VERSION ""

NS_ :

BS_:

BU_: XXX RADAR

BO_ 85 EPB: 8 XXX
 SG_ EPB_ActiveFlag : 40|1@1+ (1,0) [0|1] "" XXX
 SG_ CheckSum : 56|8@1+ (1,0) [0|255] "" XXX

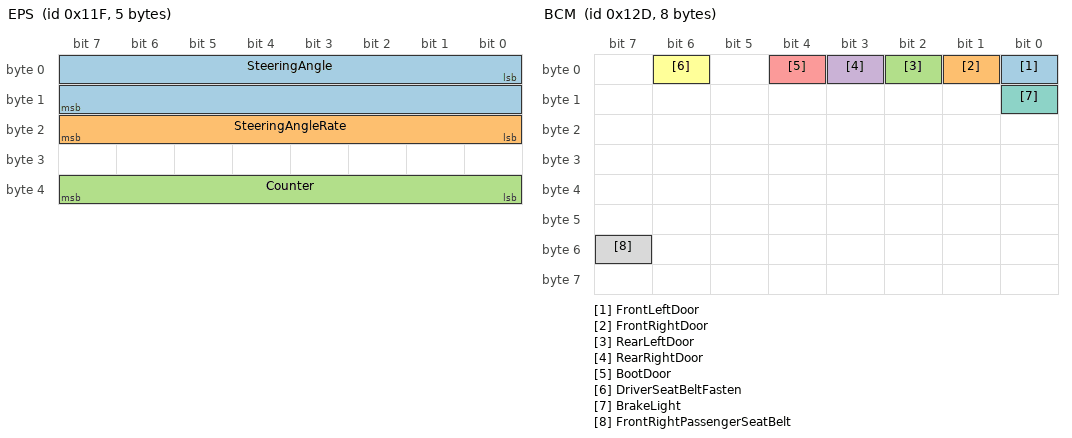
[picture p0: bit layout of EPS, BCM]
BO_ 287 EPS: 5 XXX
 SG_ SteeringAngle : 0|16@1- (0.1,0) [-450|450] "" XXX
 SG_ SteeringAngleRate : 16|8@1+ (4,0) [0|1020] "" XXX
 SG_ Counter : 32|8@1+ (1,0) [0|255] "" XXX

BO_ 289 CARSPEED: 8 XXX
 SG_ CarDisplaySpeed : 0|12@1+ (1,0) [0|255] "" XXX

BO_ 301 BCM: 8 XXX
 SG_ FrontLeftDoor : 0|1@0+ (1,0) [0|1] "" XXX
 SG_ FrontRightDoor : 1|1@0+ (1,0) [0|1] "" XXX
 SG_ RearLeftDoor : 2|1@0+ (1,0) [0|1] "" XXX
 SG_ RearRightDoor : 3|1@0+ (1,0) [0|1] "" XXX
 SG_ BootDoor : 4|1@0+ (1,0) [0|1] "" XXX
 SG_ DriverSeatBeltFasten : 6|1@0+ (1,0) [0|1] "" XXX
 SG_ BrakeLight : 8|1@0+ (1,0) [0|1] "" XXX
 SG_ FrontRightPassengerSeatBelt : 55|1@0+ (1,0) [0|1] "" XXX

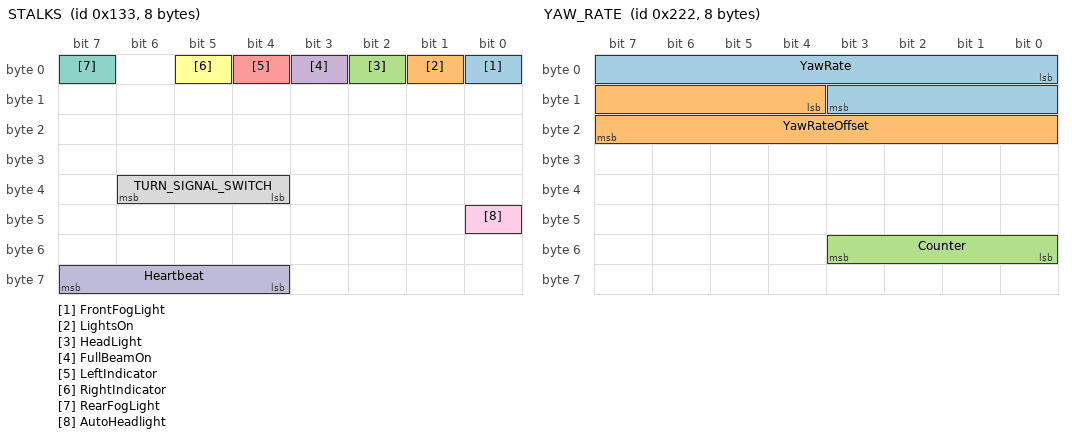
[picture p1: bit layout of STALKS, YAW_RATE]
BO_ 307 STALKS: 8 XXX
 SG_ FrontFogLight : 0|1@0+ (1,0) [0|1] "" XXX
 SG_ LightsOn : 1|1@1+ (1,0) [0|1] "" XXX
 SG_ HeadLight : 2|1@1+ (1,0) [0|1] "" XXX
 SG_ FullBeamOn : 3|1@1+ (1,0) [0|1] "" XXX
 SG_ LeftIndicator : 4|1@0+ (1,0) [0|1] "" XXX
 SG_ RightIndicator : 5|1@0+ (1,0) [0|1] "" XXX
 SG_ RearFogLight : 7|1@0+ (1,0) [0|1] "" XXX
 SG_ TURN_SIGNAL_SWITCH : 36|3@1+ (1,0) [0|7] "" XXX
 SG_ AutoHeadlight : 40|1@0+ (1,0) [0|1] "" XXX
 SG_ Heartbeat : 63|4@0+ (1,0) [0|15] "" XXX

BO_ 546 YAW_RATE: 8 XXX
 SG_ YawRate : 0|12@1+ (0.002133,-2.094) [-2|2] "rad/s" XXX
 SG_ YawRateOffset : 12|12@1+ (0.002133,-0.13) [-0.1|0.1] "rad/s" XXX
 SG_ Counter : 48|4@1+ (1,0) [0|15] "" XXX

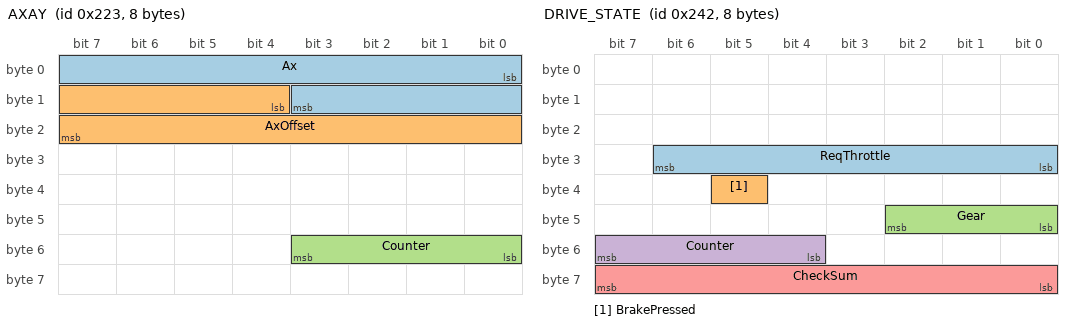
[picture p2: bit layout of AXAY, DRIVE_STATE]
BO_ 547 AXAY: 8 XXX
 SG_ Ax : 0|12@1+ (0.027167,-21.593) [-10|10] "m/s^2" XXX
 SG_ AxOffset : 12|12@1+ (0.027127,-21.593) [-1|1] "m/s^2" XXX
 SG_ Counter : 48|4@1+ (1,0) [0|15] "" XXX

BO_ 578 DRIVE_STATE: 8 XXX
 SG_ ReqThrottle : 30|7@0+ (1,0) [0|127] "" XXX
 SG_ BrakePressed : 37|1@0+ (1,0) [0|1] "" XXX
 SG_ Gear : 40|3@1+ (1,0) [0|7] "" XXX
 SG_ Counter : 55|4@0+ (1,0) [0|15] "" XXX
 SG_ CheckSum : 56|8@1+ (1,0) [0|255] "" XXX

BO_ 660 BELT: 8 XXX
 SG_ SeatBeat : 16|2@1+ (1,0) [0|3] "" XXX

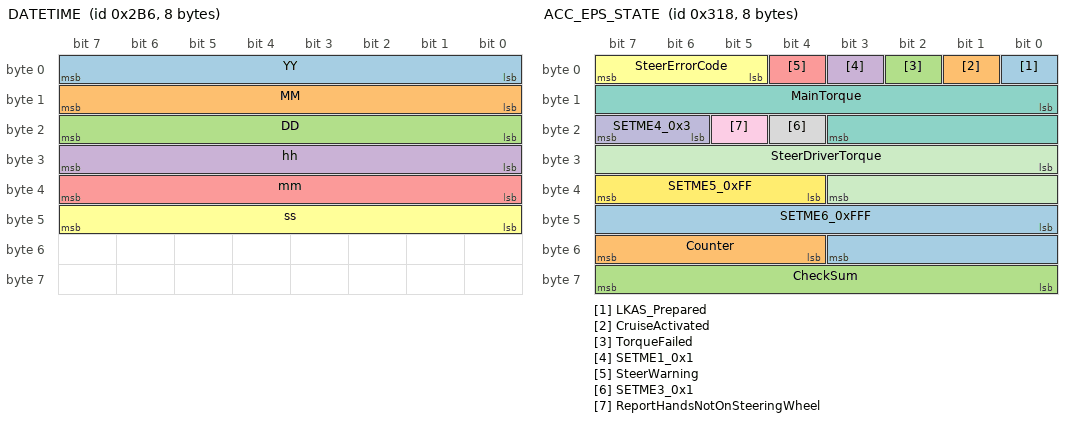
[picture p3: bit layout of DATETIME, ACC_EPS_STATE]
BO_ 694 DATETIME: 8 XXX
 SG_ YY : 7|8@0+ (1,0) [0|255] "" XXX
 SG_ MM : 15|8@0+ (1,0) [0|255] "" XXX
 SG_ DD : 23|8@0+ (1,0) [0|255] "" XXX
 SG_ hh : 31|8@0+ (1,0) [0|255] "" XXX
 SG_ mm : 39|8@0+ (1,0) [0|255] "" XXX
 SG_ ss : 47|8@0+ (1,0) [0|255] "" XXX

BO_ 790 ACC_MPC_STATE: 8 XXX
 SG_ AutoFullBeamState : 3|4@0+ (1,0) [0|1] "" XXX
 SG_ LeftLaneState : 4|2@1+ (1,0) [0|3] "" XXX
 SG_ LKAS_Config : 6|2@1+ (1,0) [0|3] "" XXX
 SG_ SETME2_0x1 : 8|2@1+ (1,0) [0|3] "" XXX
 SG_ ReqHandsOnSteeringWheel : 10|1@1+ (1,0) [0|1] "" XXX
 SG_ MPC_State : 11|4@1+ (1,0) [0|1] "" XXX
 SG_ AutoFullBeam_OnOff : 15|1@0+ (1,0) [0|1] "" XXX
 SG_ LKAS_Output : 16|11@1- (1,0) [-1024|1023] "" XXX
 SG_ LKAS_ReqPrepare : 27|1@1+ (1,0) [0|1] "" XXX
 SG_ LKAS_Active : 28|1@1+ (1,0) [0|3] "" XXX
 SG_ SETME3_0x0 : 29|1@0+ (1,0) [0|1] "" XXX
 SG_ TrafficSignRecognition_OnOff : 30|1@0+ (1,0) [0|1] "" XXX
 SG_ SETME4_0x0 : 31|1@0+ (1,0) [0|1] "" XXX
 SG_ SETME5_0x1 : 32|2@1+ (1,0) [0|3] "" XXX
 SG_ RightLaneState : 34|2@1+ (1,0) [0|3] "" XXX
 SG_ LKAS_State : 36|4@1+ (1,0) [0|3] "" XXX
 SG_ TrafficSignRecognition_Result : 40|8@1+ (5,-5) [-5|1270] "" XXX
 SG_ LKAS_AlarmType : 49|2@0+ (1,0) [0|3] "" XXX
 SG_ SETME7_0x3 : 51|2@0+ (1,0) [0|3] "" XXX
 SG_ Counter : 52|4@1+ (1,0) [0|15] "" XXX
 SG_ CheckSum : 56|8@1+ (1,0) [0|15] "" XXX

BO_ 792 ACC_EPS_STATE: 8 XXX
 SG_ LKAS_Prepared : 0|1@1+ (1,0) [0|1] "" XXX
 SG_ CruiseActivated : 1|1@1+ (1,0) [0|1] "" XXX
 SG_ TorqueFailed : 2|1@1+ (1,0) [0|1] "" XXX
 SG_ SETME1_0x1 : 3|1@1+ (1,0) [0|1] "" XXX
 SG_ SteerWarning : 4|1@1+ (1,0) [0|1] "" XXX
 SG_ SteerErrorCode : 5|3@1+ (1,0) [0|1] "" XXX
 SG_ MainTorque : 8|12@1- (1,0) [-2048|2047] "" XXX
 SG_ SETME3_0x1 : 20|1@1+ (1,0) [0|1] "" XXX
 SG_ ReportHandsNotOnSteeringWheel : 21|1@1+ (1,0) [0|1] "" XXX
 SG_ SETME4_0x3 : 22|2@1+ (1,0) [0|15] "" XXX
 SG_ SteerDriverTorque : 24|12@1- (1,0) [-2048|2047] "" XXX
 SG_ SETME5_0xFF : 36|4@1+ (1,0) [0|15] "" XXX
 SG_ SETME6_0xFFF : 40|12@1+ (1,0) [0|4095] "" XXX
 SG_ Counter : 52|4@1+ (1,0) [0|15] "" XXX
 SG_ CheckSum : 56|8@1+ (1,0) [0|255] "" XXX

BO_ 813 ACC_HUD_ADAS: 8 XXX
 SG_ SetSpeed : 0|9@1+ (0.5,0) [0|255.5] "" XXX
 SG_ HasLead : 9|1@1+ (1,0) [0|1] "" XXX
 SG_ SetDistance : 10|3@1+ (1,0) [0|7] "" XXX
 SG_ LeadingDistance : 13|3@1+ (1,0) [0|7] "" XXX
 SG_ AEB : 16|1@1+ (1,0) [0|1] "" XXX
 SG_ FCW : 17|1@1+ (1,0) [0|1] "" XXX
 SG_ SETME1_0x1 : 18|1@1+ (1,0) [0|1] "" XXX
 SG_ AccState : 19|3@1+ (1,0) [0|1] "" XXX
 SG_ AccOn1 : 22|1@0+ (1,0) [0|1] "" XXX
 SG_ CloseWarning : 23|1@0+ (1,0) [0|1] "" XXX
 SG_ SETME2_0x1 : 24|1@1+ (1,0) [0|1] "" XXX
 SG_ Notify : 25|7@1+ (1,0) [0|127] "" XXX
 SG_ Status : 32|4@1+ (1,0) [0|15] "" XXX
 SG_ SETME3_0xFFF : 36|12@1+ (1,0) [0|4095] "" XXX
 SG_ Counter : 48|4@1+ (1,0) [0|15] "" XXX
 SG_ SETME4_0xF : 55|4@0+ (1,0) [0|15] "" XXX
 SG_ CheckSum : 56|8@1+ (1,0) [0|255] "" XXX

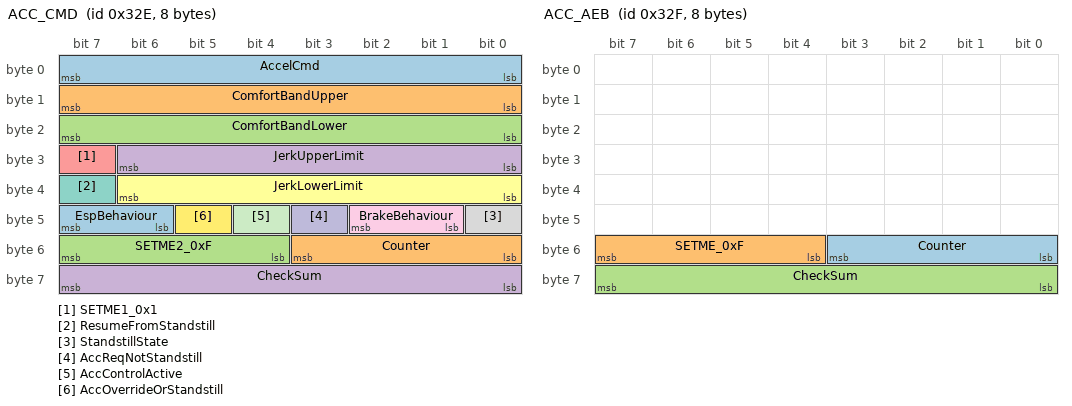
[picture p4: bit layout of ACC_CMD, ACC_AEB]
BO_ 814 ACC_CMD: 8 XXX
 SG_ AccelCmd : 0|8@1+ (0.05,-5) [-100|155] "" XXX
 SG_ ComfortBandUpper : 8|8@1+ (0.05,-5) [0|1.26] "" XXX
 SG_ ComfortBandLower : 16|8@1+ (0.05,-5) [0|1.26] "" XXX
 SG_ JerkUpperLimit : 24|7@1+ (0.2,0) [0|12.7] "" XXX
 SG_ SETME1_0x1 : 31|1@0+ (1,0) [0|1] "" XXX
 SG_ JerkLowerLimit : 32|7@1+ (0.2,-16) [0|12.7] "" XXX
 SG_ ResumeFromStandstill : 39|1@0+ (1,0) [0|1] "" XXX
 SG_ StandstillState : 40|1@0+ (1,0) [0|1] "" XXX
 SG_ BrakeBehaviour : 41|2@1+ (1,0) [0|3] "" XXX
 SG_ AccReqNotStandstill : 43|1@1+ (1,0) [0|1] "" XXX
 SG_ AccControlActive : 44|1@0+ (1,0) [0|1] "" XXX
 SG_ AccOverrideOrStandstill : 45|1@0+ (1,0) [0|1] "" XXX
 SG_ EspBehaviour : 46|2@1+ (1,0) [0|3] "" XXX
 SG_ Counter : 48|4@1+ (1,0) [0|15] "" XXX
 SG_ SETME2_0xF : 55|4@0+ (1,0) [0|15] "" XXX
 SG_ CheckSum : 56|8@1+ (1,0) [0|255] "" XXX

BO_ 815 ACC_AEB: 8 XXX
 SG_ Counter : 48|4@1+ (1,0) [0|15] "" XXX
 SG_ SETME_0xF : 55|4@0+ (1,0) [0|15] "" XXX
 SG_ CheckSum : 56|8@1+ (1,0) [0|255] "" XXX

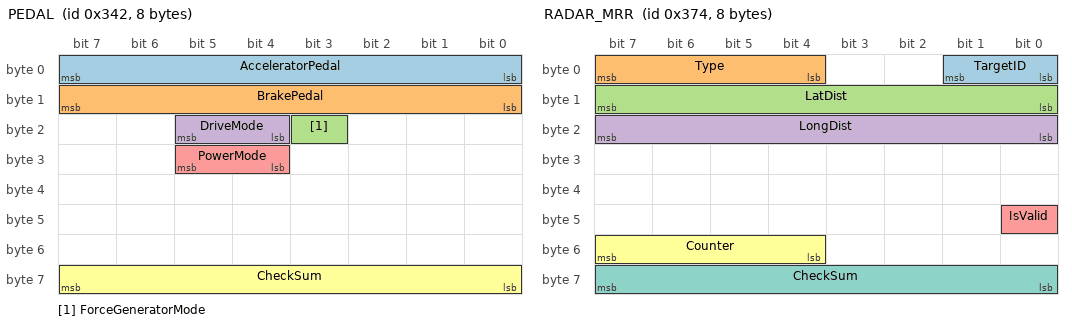
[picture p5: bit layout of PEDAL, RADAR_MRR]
BO_ 834 PEDAL: 8 XXX
 SG_ AcceleratorPedal : 0|8@1+ (0.01,0) [0|255] "" XXX
 SG_ BrakePedal : 8|8@1+ (0.01,0) [0|255] "" XXX
 SG_ ForceGeneratorMode : 19|1@1+ (1,0) [0|1] "" XXX
 SG_ DriveMode : 20|2@1+ (1,0) [0|255] "" XXX
 SG_ PowerMode : 28|2@1+ (1,0) [0|1] "" XXX
 SG_ CheckSum : 56|8@1+ (1,0) [0|255] "" XXX

BO_ 884 RADAR_MRR: 8 XXX
 SG_ TargetID : 1|2@0+ (1,0) [0|3] "" XXX
 SG_ Type : 7|4@0+ (1,0) [0|15] "" XXX
 SG_ LatDist : 15|8@0+ (0.1,-12) [0|255] "" XXX
 SG_ LongDist : 23|8@0+ (1,-100) [0|255] "" XXX
 SG_ IsValid : 40|1@0+ (1,0) [0|3] "" XXX
 SG_ Counter : 52|4@1+ (1,0) [0|15] "" XXX
 SG_ CheckSum : 56|8@1+ (1,0) [0|255] "" XXX

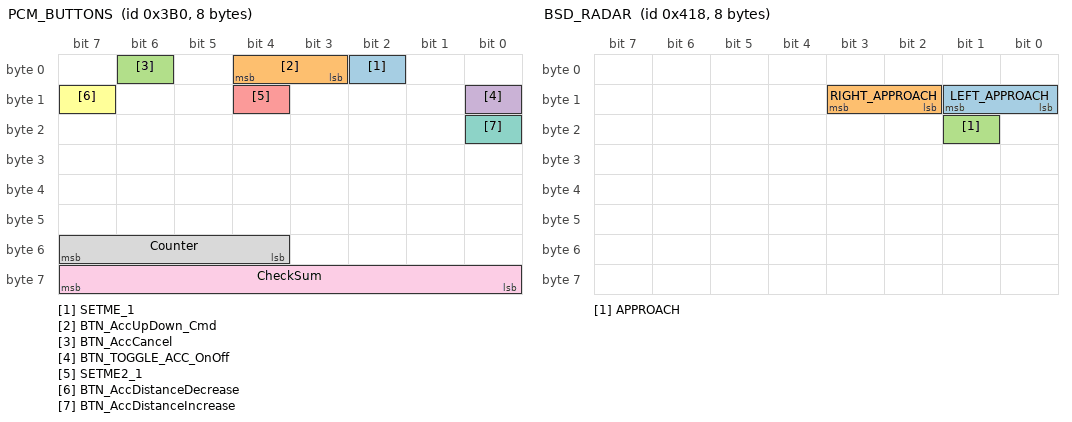
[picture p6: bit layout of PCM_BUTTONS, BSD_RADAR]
BO_ 944 PCM_BUTTONS: 8 XXX
 SG_ SETME_1 : 2|1@0+ (1,0) [0|1] "" XXX
 SG_ BTN_AccUpDown_Cmd : 4|2@0+ (1,0) [0|3] "" XXX
 SG_ BTN_AccCancel : 6|1@0+ (1,0) [0|1] "" XXX
 SG_ BTN_TOGGLE_ACC_OnOff : 8|1@0+ (1,0) [0|1] "" XXX
 SG_ SETME2_1 : 12|1@0+ (1,0) [0|1] "" XXX
 SG_ BTN_AccDistanceDecrease : 15|1@0+ (1,0) [0|1] "" XXX
 SG_ BTN_AccDistanceIncrease : 16|1@0+ (1,0) [0|1] "" XXX
 SG_ Counter : 52|4@1+ (1,0) [0|15] "" XXX
 SG_ CheckSum : 56|8@1+ (1,0) [0|255] "" XXX

BO_ 1048 BSD_RADAR: 8 XXX
 SG_ LEFT_APPROACH : 9|2@0+ (1,0) [0|1] "" XXX
 SG_ RIGHT_APPROACH : 11|2@0+ (1,0) [0|1] "" XXX
 SG_ APPROACH : 17|1@0+ (1,0) [0|1] "" XXX
VAL_ 578 Gear 4 "D" 2 "R" 3 "N" 1 "P";
VAL_ 790 AutoFullBeamState 11 "AutoFullBeamActive" 2 "AutoFullBeamInactive";
VAL_ 790 LeftLaneState 0 "GRAY" 1 "GREEN" 2 "YELLOW" 3 "RED";
VAL_ 790 LKAS_Config 3 "ALARM_AND_LKA" 2 "LKA" 1 "ALARM" 0 "DISABLE";
VAL_ 790 RightLaneState 0 "GRAY" 1 "GREEN" 2 "YELLOW" 3 "RED";
VAL_ 790 LKAS_AlarmType 0 "VIBRATION" 1 "AUDIO" 2 "AUDIO_AND_VIBRATION";
VAL_ 792 LKAS_Prepared 0 "NotReady" 1 "Ready" 2 "Active" 3 "TemporaryFail";
VAL_ 813 SetDistance 4 "4BAR" 3 "3BAR" 2 "2BAR" 1 "1BAR";
VAL_ 813 AccState 0 "OFF" 2 "ACC_ON" 3 "ACC_ACTIVE" 5 "FORCE_ACCEL" 7 "ERROR";
VAL_ 813 Notify 36 "ACC_ERROR" 22 "OVERRIDE" 12 "ENGAGE" 8 "DISENGAGE" 20 "ACC_ON" 32 "ACC_OFF" 48 "CHECK_GEAR_D" 16 "FORCE_ACCEL" 0 "NONE";
VAL_ 814 AccOverrideOrStandstill 0 "Off" 1 "Passive" 2 "StandBy" 3 "ActiveControl" 4 "BrakeOnly" 5 "Override" 6 "Standstill" 7 "Failure";
VAL_ 814 EspBehaviour 0 "Softoff" 1 "Fastoff" 2 "Immediateoff" 3 "Initial";
VAL_ 834 DriveMode 2 "SPORT" 1 "ECO" 0 "SNOW";
VAL_ 834 PowerMode 3 "HEV" 2 "FORCE_EV" 1 "EV";
VAL_ 944 BTN_AccUpDown_Cmd 0 "NOTPRESSED" 1 "DOWN_SETSPEED" 3 "UP_RESETSPEED";

BO_ 265 RADAR_MAIN_TARGET: 8 RADAR
CM_ BO_ 265 " Main target 0x109: MainDist = 0.5*b7 - 4 (VERIFIED 1.1M frames 100%)";
 SG_ MainDist : 56|8@1+ (0.5,-4) [0|255] "m" RADAR

BO_ 832 RADAR_340: 8 RADAR
CM_ BO_ 832 " 0x340 b7 azimuth, 128 center (main target bearing)";
 SG_ AzimB7 : 56|8@1+ (1,-128) [-128|127] "deg" RADAR

BO_ 897 RADAR_381: 8 RADAR
CM_ BO_ 897 " PoolA slot0 base+1 (0x381): dRel=0.4244*dat[3]+17.79, Azim=b6-128 (VERIFIED)";
 SG_ AzimSub0 : 48|8@1+ (1,-128) [-128|127] "deg" RADAR
 SG_ dRel_slot0b : 24|8@1+ (0.4244,17.79) [0|255] "m" RADAR

BO_ 901 RADAR_385: 8 RADAR
CM_ BO_ 901 " PoolA slot1 base+1 (0x385): dRel=0.4244*dat[3]+17.79, Azim=b6-128 (VERIFIED)";
 SG_ AzimSub1 : 48|8@1+ (1,-128) [-128|127] "deg" RADAR
 SG_ dRel_slot1b : 24|8@1+ (0.4244,17.79) [0|255] "m" RADAR

BO_ 905 RADAR_389: 8 RADAR
CM_ BO_ 905 " PoolA slot2 base+1 (0x389): dRel=0.4244*dat[3]+17.79, Azim=b6-128 (VERIFIED)";
 SG_ AzimSub2 : 48|8@1+ (1,-128) [-128|127] "deg" RADAR
 SG_ dRel_slot2b : 24|8@1+ (0.4244,17.79) [0|255] "m" RADAR

BO_ 909 RADAR_38D: 8 RADAR
CM_ BO_ 909 " PoolA slot3 base+1 (0x38D): dRel=0.4244*dat[3]+17.79, Azim=b6-128 (VERIFIED)";
 SG_ AzimSub3 : 48|8@1+ (1,-128) [-128|127] "deg" RADAR
 SG_ dRel_slot3b : 24|8@1+ (0.4244,17.79) [0|255] "m" RADAR

BO_ 913 RADAR_391: 8 RADAR
CM_ BO_ 913 " PoolA slot4 base+1 (0x391): dRel=0.4244*dat[3]+17.79, Azim=b6-128 (VERIFIED)";
 SG_ AzimSub4 : 48|8@1+ (1,-128) [-128|127] "deg" RADAR
 SG_ dRel_slot4b : 24|8@1+ (0.4244,17.79) [0|255] "m" RADAR

BO_ 917 RADAR_395: 8 RADAR
CM_ BO_ 917 " PoolA slot5 base+1 (0x395): dRel=0.4244*dat[3]+17.79, Azim=b6-128 (VERIFIED)";
 SG_ AzimSub5 : 48|8@1+ (1,-128) [-128|127] "deg" RADAR
 SG_ dRel_slot5b : 24|8@1+ (0.4244,17.79) [0|255] "m" RADAR

# ===== 2026-08-27 真实路试补充 (bus1 雷达, 记忆 RADAR_ADDRESS_MAP 完整解码) =====
# 目标族 0x100-108 (256-264): 心跳/时序, 常量帧
BO_ 256 RADAR_100: 8 RADAR
 SG_ Cnt0 : 0|8@1+ (1,0) [0|255] "" RADAR
BO_ 257 RADAR_101: 8 RADAR
 SG_ Cnt1 : 0|8@1+ (1,0) [0|255] "" RADAR
BO_ 258 RADAR_102: 8 RADAR
 SG_ Cnt2 : 0|8@1+ (1,0) [0|255] "" RADAR
BO_ 259 RADAR_103: 8 RADAR
 SG_ Cnt3 : 0|8@1+ (1,0) [0|255] "" RADAR
BO_ 260 RADAR_104: 8 RADAR
 SG_ Cnt4 : 0|8@1+ (1,0) [0|255] "" RADAR
BO_ 261 RADAR_105: 8 RADAR
 SG_ Cnt5 : 0|8@1+ (1,0) [0|255] "" RADAR
BO_ 262 RADAR_106: 8 RADAR
 SG_ Cnt6 : 0|8@1+ (1,0) [0|255] "" RADAR
BO_ 263 RADAR_107: 8 RADAR
 SG_ Cnt7 : 0|8@1+ (1,0) [0|255] "" RADAR
BO_ 264 RADAR_108: 8 RADAR
 SG_ Cnt8 : 0|8@1+ (1,0) [0|255] "" RADAR
# 第二目标速度 0x10A (266): b7 = 0.803*b7 - 98.2 (r=0.75)
BO_ 266 RADAR_10A: 8 RADAR
CM_ BO_ 266 " 0x10A Second target speed v = 0.803*b7 - 98.2 (VERIFIED)";
 SG_ SecondVRel : 56|8@1+ (0.803,-98.2) [-100|100] "m/s" RADAR
# 心跳 0x350-354 (848-852): 纯心跳, b0/b1 计数+滚动码
BO_ 848 RADAR_350: 8 RADAR
 SG_ Roll350 : 8|8@1+ (1,0) [0|255] "" RADAR
BO_ 849 RADAR_351: 8 RADAR
 SG_ Roll351 : 8|8@1+ (1,0) [0|255] "" RADAR
BO_ 850 RADAR_352: 8 RADAR
 SG_ Roll352 : 8|8@1+ (1,0) [0|255] "" RADAR
BO_ 851 RADAR_353: 8 RADAR
 SG_ Roll353 : 8|8@1+ (1,0) [0|255] "" RADAR
BO_ 852 RADAR_354: 8 RADAR
 SG_ Roll354 : 8|8@1+ (1,0) [0|255] "" RADAR
# 扩展目标池B 槽0 0x3C8 (968): 距离 b3 = 0.4244*b3 + 17.79 (同池A公式, VERIFIED)
BO_ 968 RADAR_3C8: 8 RADAR
CM_ BO_ 968 " PoolB slot0 (0x3C8): dRel = 0.4244*dat[3] + 17.79 (VERIFIED)";
 SG_ dRel_slotB0 : 24|8@1+ (0.4244,17.79) [0|255] "m" RADAR
# 状态帧 0x301/302 (769/770)
BO_ 769 RADAR_301: 8 RADAR
 SG_ Status301 : 0|8@1+ (1,0) [0|255] "" RADAR
BO_ 770 RADAR_302: 8 RADAR
 SG_ Status302 : 0|8@1+ (1,0) [0|255] "" RADAR
# EKU 诊断 0x7FE7A00 (134117888): b1 自车速度广播 (粗)
BO_ 134117888 EKU_SPEED: 8 RADAR
 SG_ EgoSpeed : 8|8@1+ (1,0) [0|255] "m/s" RADAR
